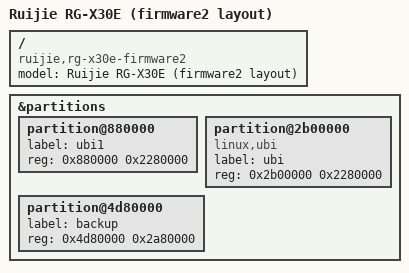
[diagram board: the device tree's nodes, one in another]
// SPDX-License-Identifier: GPL-2.0-or-later OR MIT
/*
 * Ruijie RG-X30E - firmware2 布局（原厂从第二个 ubi 槽启动的机器用这个）
 * 与 stock 布局唯一区别是 ubi1/ubi 的标签与偏移互换。
 */

/dts-v1/;
#include "mt7981b-ruijie-rg-x30e.dtsi"

/ {
	model = "Ruijie RG-X30E (firmware2 layout)";
	compatible = "ruijie,rg-x30e-firmware2", "mediatek,mt7981";
};

&partitions {
	partition@880000 {
		label = "ubi1";
		reg = <0x880000 0x2280000>;
	};

	partition@2b00000 {
		label = "ubi";
		reg = <0x2b00000 0x2280000>;
		compatible = "linux,ubi";
	};

	partition@4d80000 {
		label = "backup";
		reg = <0x4d80000 0x2a80000>;
	};
};
